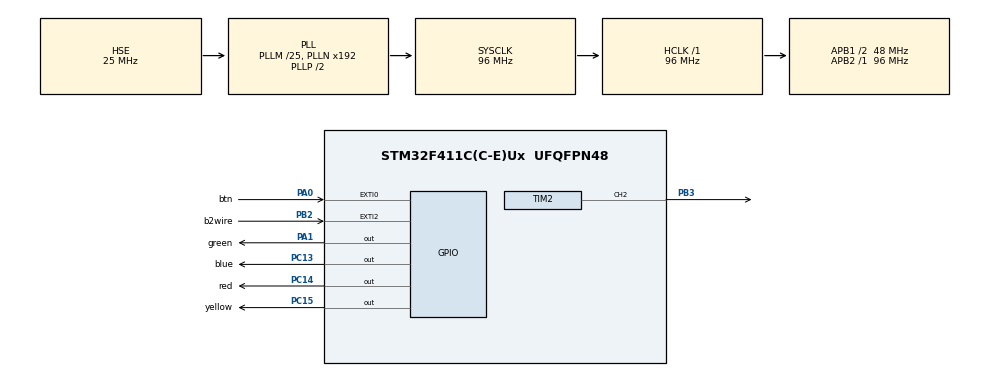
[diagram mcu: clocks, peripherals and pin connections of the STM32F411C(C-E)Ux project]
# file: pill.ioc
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Dma.Request0=TIM2_CH2/CH4
Dma.TIM2_CH2/CH4.0.Direction=DMA_MEMORY_TO_PERIPH
Dma.TIM2_CH2/CH4.0.FIFOMode=DMA_FIFOMODE_DISABLE
Dma.TIM2_CH2/CH4.0.Instance=DMA1_Stream6
Dma.TIM2_CH2/CH4.0.MemDataAlignment=DMA_MDATAALIGN_WORD
Dma.TIM2_CH2/CH4.0.MemInc=DMA_MINC_ENABLE
Dma.TIM2_CH2/CH4.0.Mode=DMA_NORMAL
Dma.TIM2_CH2/CH4.0.PeriphDataAlignment=DMA_PDATAALIGN_WORD
Dma.TIM2_CH2/CH4.0.PeriphInc=DMA_PINC_DISABLE
Dma.TIM2_CH2/CH4.0.Priority=DMA_PRIORITY_LOW
Mcu.Family=STM32F4
Mcu.Name=STM32F411C(C-E)Ux
Mcu.Package=UFQFPN48
NVIC.DMA1_Stream6_IRQn=true\:0\:0\:false\:false\:true\:false\:true\:true
NVIC.EXTI2_IRQn=true\:0\:0\:false\:false\:true\:true\:true\:true
NVIC.FPU_IRQn=true\:0\:0\:false\:false\:true\:true\:false\:true
NVIC.PriorityGroup=NVIC_PRIORITYGROUP_4
NVIC.RCC_IRQn=true\:0\:0\:false\:false\:true\:true\:false\:true
PA0-WKUP.GPIO_Label=btn
PA0-WKUP.Signal=GPXTI0
PA1.GPIO_Label=green
PA1.Signal=GPIO_Output
PA13.Mode=Serial_Wire
PA13.Signal=SYS_JTMS-SWDIO
PA14.Mode=Serial_Wire
PA14.Signal=SYS_JTCK-SWCLK
PB2.GPIO_Label=b2wire
PB2.Signal=GPXTI2
PB3.Signal=S_TIM2_CH2
PC13-ANTI_TAMP.GPIO_Label=blue
PC13-ANTI_TAMP.Signal=GPIO_Output
PC14-OSC32_IN.GPIO_Label=red
PC14-OSC32_IN.Signal=GPIO_Output
PC15-OSC32_OUT.GPIO_Label=yellow
PC15-OSC32_OUT.Signal=GPIO_Output
PH0\ -\ OSC_IN.Mode=HSE-External-Oscillator
PH0\ -\ OSC_IN.Signal=RCC_OSC_IN
PH1\ -\ OSC_OUT.Mode=HSE-External-Oscillator
PH1\ -\ OSC_OUT.Signal=RCC_OSC_OUT
ProjectManager.HeapSize=0x200
ProjectManager.StackSize=0x400
ProjectManager.TargetToolchain=STM32CubeIDE
RCC.48MHZClocksFreq_Value=48000000
RCC.AHBFreq_Value=96000000
RCC.APB1CLKDivider=RCC_HCLK_DIV2
RCC.APB1Freq_Value=48000000
RCC.APB1TimFreq_Value=96000000
RCC.APB2Freq_Value=96000000
RCC.APB2TimFreq_Value=96000000
RCC.CortexFreq_Value=96000000
RCC.HCLKFreq_Value=96000000
RCC.HSE_VALUE=25000000
RCC.HSI_VALUE=16000000
RCC.LSE_VALUE=32768
RCC.PLLM=25
RCC.PLLSourceVirtual=RCC_PLLSOURCE_HSE
RCC.SYSCLKFreq_VALUE=96000000
RCC.SYSCLKSource=RCC_SYSCLKSOURCE_PLLCLK
RCC.VCOOutputFreq_Value=192000000
SH.S_TIM2_CH2.0=TIM2_CH2,PWM Generation2 CH2
TIM2.Channel-PWM\ Generation2\ CH2=TIM_CHANNEL_2
TIM2.Period=100-1
TIM2.Prescaler=9600
VP_TIM2_VS_ClockSourceINT.Mode=Internal
board=custom

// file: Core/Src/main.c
/* USER CODE BEGIN Header */
/**
  ******************************************************************************
  * @file           : main.c
  * @brief          : Main program body
  ******************************************************************************
  * @attention
  *
  * Copyright (c) 2022 STMicroelectronics.
  * All rights reserved.
  *
  * This software is licensed under terms that can be found in the LICENSE file
  * in the root directory of this software component.
  * If no LICENSE file comes with this software, it is provided AS-IS.
  *
  ******************************************************************************
  */
/* USER CODE END Header */
#include "main.h"

TIM_HandleTypeDef htim2;
DMA_HandleTypeDef hdma_tim2_ch2_ch4;

/* USER CODE BEGIN PV */
uint8_t flag=0;
uint8_t flagCount=0;
uint8_t flagBtn=0;
uint16_t timVal;
/* USER CODE END PV */

void SystemClock_Config(void);
static void MX_GPIO_Init(void);
static void MX_DMA_Init(void);
static void MX_TIM2_Init(void);

/* USER CODE BEGIN 0 */

//for pmw
uint16_t pwmData[10];

/* USER CODE END 0 */

int main(void)
{

  /* MCU Configuration--------------------------------------------------------*/

  /* Reset of all peripherals, Initializes the Flash interface and the Systick. */
  HAL_Init();

  /* Configure the system clock */
  SystemClock_Config();

  /* USER CODE BEGIN SysInit */

  //for statemachine
//  static void buttonPress(void);
//  static void setupSys(void);

  /* USER CODE END SysInit */

  /* Initialize all configured peripherals */
  MX_GPIO_Init();
  MX_DMA_Init();
  MX_TIM2_Init();
  /* USER CODE BEGIN 2 */

  //select channel counter value
  TIM2 -> CCR2 = 5;
  HAL_TIM_PWM_Start(&htim2, TIM_CHANNEL_2);
//  pwmData[0] = 10;
//  pwmData[1] = 20;
//  pwmData[2] = 30;
//  pwmData[3] = 40;
//  pwmData[4] = 50;
//  pwmData[5] = 60;
//  pwmData[6] = 70;
//  pwmData[7] = 80;
//  pwmData[8] = 90;
//  pwmData[9] = 100;
//
//  HAL_TIM_PWM_Start_DMA(&htim2, TIM_CHANNEL_2, (uint32_t *)pwmData, 10);

  //STart timer
//  HAL_TIM_Base_Start(&htim11);
//  timVal = __HAL_TIM_GET_COUNTER(&htim11);

  //timer interrupt
//  HAL_TIM_Base_Start_IT(&htim11)

  //typedef enum {}eSystemState;
//  enum state {Red, Green, Yellow};
//  enum state current_state = Red;

  /* USER CODE END 2 */

  /* Infinite loop */
  /* USER CODE BEGIN WHILE */
  while (1)
  {

//with tim11 prescaler set to 9600-1 and counter to 65536-1
//	  if(__HAL_TIM_GET_COUNTER(&htim11) - timVal >= 10000){
//		  HAL_GPIO_TogglePin(red_GPIO_Port, red_Pin);
//		  timVal = __HAL_TIM_GET_COUNTER(&htim11);
//	  }

//brething led
//	  int x;
//	  	for(x=0; x<625; x=x+1)
//	  	{
//	  	  __HAL_TIM_SET_COMPARE(&htim2,TIM_CHANNEL_2, x);
//	  	  HAL_Delay(3);
//	  	}
//	  	for(x=625; x>0; x=x-1)
//	  	{
//	  	  __HAL_TIM_SET_COMPARE(&htim2,TIM_CHANNEL_2, x);
//	  	  HAL_Delay(3);
//	  	}

	  //	  while (current_state != Yellow){
//	  switch (current_state){
//	  case Red:
//		  HAL_GPIO_WritePin(red_GPIO_Port, red_Pin, 1);
//		  HAL_GPIO_WritePin(yellow_GPIO_Port, yellow_Pin, 0);
//		  HAL_GPIO_WritePin(green_GPIO_Port, green_Pin, 0);
//		  //if flagCount<3 || if flagBtn == 1;
//		  //set flagBtn = 0;
//		  break;
//
//
//	  case Green:
//		  HAL_GPIO_WritePin(red_GPIO_Port, red_Pin, 0);
//		  HAL_GPIO_WritePin(yellow_GPIO_Port, yellow_Pin, 0);
//		  HAL_GPIO_WritePin(green_GPIO_Port, green_Pin, 1);
//		  break;
//		  //if flagCount<6
//
//
//	  case Yellow:
//		  HAL_GPIO_WritePin(red_GPIO_Port, red_Pin, 0);
//		  HAL_GPIO_WritePin(yellow_GPIO_Port, yellow_Pin, 1);
//		  HAL_GPIO_WritePin(green_GPIO_Port, green_Pin, 0);
//		  break;
//		  //if flagCount < 7
//		  //set flagCount=0
//
//	  }

//	  }

    /* USER CODE END WHILE */

  }
}

void SystemClock_Config(void)
{
  RCC_OscInitTypeDef RCC_OscInitStruct = {0};
  RCC_ClkInitTypeDef RCC_ClkInitStruct = {0};

  /** Configure the main internal regulator output voltage
  */
  __HAL_RCC_PWR_CLK_ENABLE();
  __HAL_PWR_VOLTAGESCALING_CONFIG(PWR_REGULATOR_VOLTAGE_SCALE1);

  /** Initializes the RCC Oscillators according to the specified parameters
  * in the RCC_OscInitTypeDef structure.
  */
  RCC_OscInitStruct.OscillatorType = RCC_OSCILLATORTYPE_HSE;
  RCC_OscInitStruct.HSEState = RCC_HSE_ON;
  RCC_OscInitStruct.PLL.PLLState = RCC_PLL_ON;
  RCC_OscInitStruct.PLL.PLLSource = RCC_PLLSOURCE_HSE;
  RCC_OscInitStruct.PLL.PLLM = 25;
  RCC_OscInitStruct.PLL.PLLN = 192;
  RCC_OscInitStruct.PLL.PLLP = RCC_PLLP_DIV2;
  RCC_OscInitStruct.PLL.PLLQ = 4;
  if (HAL_RCC_OscConfig(&RCC_OscInitStruct) != HAL_OK)
  {
    Error_Handler();
  }

  /** Initializes the CPU, AHB and APB buses clocks
  */
  RCC_ClkInitStruct.ClockType = RCC_CLOCKTYPE_HCLK|RCC_CLOCKTYPE_SYSCLK
                              |RCC_CLOCKTYPE_PCLK1|RCC_CLOCKTYPE_PCLK2;
  RCC_ClkInitStruct.SYSCLKSource = RCC_SYSCLKSOURCE_PLLCLK;
  RCC_ClkInitStruct.AHBCLKDivider = RCC_SYSCLK_DIV1;
  RCC_ClkInitStruct.APB1CLKDivider = RCC_HCLK_DIV2;
  RCC_ClkInitStruct.APB2CLKDivider = RCC_HCLK_DIV1;

  if (HAL_RCC_ClockConfig(&RCC_ClkInitStruct, FLASH_LATENCY_3) != HAL_OK)
  {
    Error_Handler();
  }
}

static void MX_TIM2_Init(void)
{

  TIM_ClockConfigTypeDef sClockSourceConfig = {0};
  TIM_MasterConfigTypeDef sMasterConfig = {0};
  TIM_OC_InitTypeDef sConfigOC = {0};

  htim2.Instance = TIM2;
  htim2.Init.Prescaler = 9600;
  htim2.Init.CounterMode = TIM_COUNTERMODE_UP;
  htim2.Init.Period = 100-1;
  htim2.Init.ClockDivision = TIM_CLOCKDIVISION_DIV1;
  htim2.Init.AutoReloadPreload = TIM_AUTORELOAD_PRELOAD_DISABLE;
  if (HAL_TIM_Base_Init(&htim2) != HAL_OK)
  {
    Error_Handler();
  }
  sClockSourceConfig.ClockSource = TIM_CLOCKSOURCE_INTERNAL;
  if (HAL_TIM_ConfigClockSource(&htim2, &sClockSourceConfig) != HAL_OK)
  {
    Error_Handler();
  }
  if (HAL_TIM_PWM_Init(&htim2) != HAL_OK)
  {
    Error_Handler();
  }
  sMasterConfig.MasterOutputTrigger = TIM_TRGO_RESET;
  sMasterConfig.MasterSlaveMode = TIM_MASTERSLAVEMODE_DISABLE;
  if (HAL_TIMEx_MasterConfigSynchronization(&htim2, &sMasterConfig) != HAL_OK)
  {
    Error_Handler();
  }
  sConfigOC.OCMode = TIM_OCMODE_PWM1;
  sConfigOC.Pulse = 0;
  sConfigOC.OCPolarity = TIM_OCPOLARITY_HIGH;
  sConfigOC.OCFastMode = TIM_OCFAST_DISABLE;
  if (HAL_TIM_PWM_ConfigChannel(&htim2, &sConfigOC, TIM_CHANNEL_2) != HAL_OK)
  {
    Error_Handler();
  }
  HAL_TIM_MspPostInit(&htim2);

}

static void MX_DMA_Init(void)
{

  /* DMA controller clock enable */
  __HAL_RCC_DMA1_CLK_ENABLE();

  /* DMA interrupt init */
  /* DMA1_Stream6_IRQn interrupt configuration */
  HAL_NVIC_SetPriority(DMA1_Stream6_IRQn, 0, 0);
  HAL_NVIC_EnableIRQ(DMA1_Stream6_IRQn);

}

static void MX_GPIO_Init(void)
{
  GPIO_InitTypeDef GPIO_InitStruct = {0};

  /* GPIO Ports Clock Enable */
  __HAL_RCC_GPIOC_CLK_ENABLE();
  __HAL_RCC_GPIOH_CLK_ENABLE();
  __HAL_RCC_GPIOA_CLK_ENABLE();
  __HAL_RCC_GPIOB_CLK_ENABLE();

  /*Configure GPIO pin Output Level */
  HAL_GPIO_WritePin(GPIOC, blue_Pin|red_Pin|yellow_Pin, GPIO_PIN_RESET);

  /*Configure GPIO pin Output Level */
  HAL_GPIO_WritePin(green_GPIO_Port, green_Pin, GPIO_PIN_RESET);

  /*Configure GPIO pins : blue_Pin red_Pin yellow_Pin */
  GPIO_InitStruct.Pin = blue_Pin|red_Pin|yellow_Pin;
  GPIO_InitStruct.Mode = GPIO_MODE_OUTPUT_PP;
  GPIO_InitStruct.Pull = GPIO_NOPULL;
  GPIO_InitStruct.Speed = GPIO_SPEED_FREQ_LOW;
  HAL_GPIO_Init(GPIOC, &GPIO_InitStruct);

  /*Configure GPIO pin : btn_Pin */
  GPIO_InitStruct.Pin = btn_Pin;
  GPIO_InitStruct.Mode = GPIO_MODE_IT_RISING;
  GPIO_InitStruct.Pull = GPIO_NOPULL;
  HAL_GPIO_Init(btn_GPIO_Port, &GPIO_InitStruct);

  /*Configure GPIO pin : green_Pin */
  GPIO_InitStruct.Pin = green_Pin;
  GPIO_InitStruct.Mode = GPIO_MODE_OUTPUT_PP;
  GPIO_InitStruct.Pull = GPIO_NOPULL;
  GPIO_InitStruct.Speed = GPIO_SPEED_FREQ_LOW;
  HAL_GPIO_Init(green_GPIO_Port, &GPIO_InitStruct);

  /*Configure GPIO pin : b2wire_Pin */
  GPIO_InitStruct.Pin = b2wire_Pin;
  GPIO_InitStruct.Mode = GPIO_MODE_IT_RISING;
  GPIO_InitStruct.Pull = GPIO_NOPULL;
  HAL_GPIO_Init(b2wire_GPIO_Port, &GPIO_InitStruct);

  /* EXTI interrupt init*/
  HAL_NVIC_SetPriority(EXTI2_IRQn, 0, 0);
  HAL_NVIC_EnableIRQ(EXTI2_IRQn);

}

/* USER CODE BEGIN 4 */

//Implement the Stateflow model of the traffic light + pedestrian light.
//Make use of the push button (external interrupt) + timers and timer interrupts to transition between the three LEDs for the traffic light.
//When a button is pushed, your MCU should transition to the pedestrian light and then back again after the timer has expired.
// External Interrupt ISR Handler CallBackFun
void HAL_GPIO_EXTI_Callback(uint16_t GPIO_Pin)
{
	flagBtn=1;
//    if(GPIO_Pin == b2wire_Pin && flag <= 1) // INT Source is pin A9
////    {
////    	HAL_GPIO_WritePin(blue_GPIO_Port, blue_Pin, 1);
////    	//		HAL_GPIO_TogglePin(red_GPIO_Port, red_Pin);
////
////    } else if (GPIO_Pin == b2wire_Pin && flag <= 5){
////    	HAL_GPIO_WritePin(red_GPIO_Port, red_Pin, 1);
////    	HAL_GPIO_WritePin(yellow_GPIO_Port, yellow_Pin, 0);
////    	HAL_GPIO_WritePin(green_GPIO_Port, green_Pin, 0);
////    	flag ++;
////    }
////    else if (GPIO_Pin == b2wire_Pin && flag <= 6){
////    	HAL_GPIO_WritePin(blue_GPIO_Port, blue_Pin, 1);
////    	flag = 0;
////    }
//
//
//    {
//
//    	HAL_GPIO_WritePin(blue_GPIO_Port, blue_Pin, 1);
//    	HAL_Delay(1000);
//    	HAL_GPIO_WritePin(red_GPIO_Port, red_Pin, 1);
//    	HAL_Delay(3000);
//    	flag = 0;
//
//    	//    			 flagCount=1;
//
//    }

}

//timer reset interrupt
void HAL_TIM_PeriodElapsedCallback(TIM_HandleTypeDef *htim)
{
//	if(htim == &htim11 && flagCount <= 2){
//		 HAL_GPIO_WritePin(red_GPIO_Port, red_Pin, 1);
//		 HAL_GPIO_WritePin(yellow_GPIO_Port, yellow_Pin, 0);
//		 HAL_GPIO_WritePin(green_GPIO_Port, green_Pin, 0);
////		HAL_GPIO_TogglePin(red_GPIO_Port, red_Pin);
//		flagCount ++;
//		flag ++;
//	} else if (htim == &htim11 && flagCount <= 3){
//		HAL_GPIO_WritePin(red_GPIO_Port, red_Pin, 0);
//		HAL_GPIO_WritePin(yellow_GPIO_Port, yellow_Pin, 1);
//		HAL_GPIO_WritePin(green_GPIO_Port, green_Pin, 0);
//		flagCount ++;
//		flag ++;
//	} else if (htim == &htim11 && flagCount <= 5){
//		HAL_GPIO_WritePin(red_GPIO_Port, red_Pin, 0);
//		HAL_GPIO_WritePin(yellow_GPIO_Port, yellow_Pin, 0);
//		HAL_GPIO_WritePin(green_GPIO_Port, green_Pin, 1);
//		flag ++;
//		flagCount ++;
//	}
//	else if (htim == &htim11 && flagCount <= 6){
//		flagCount = 0;
//	}
	flagCount = 1;

}

/* USER CODE END 4 */

void Error_Handler(void)
{
  __disable_irq();
  while (1)
  {
  }
}
